# max32657 register map
Vendor: Maxim-Integrated; Series: ARMCM33; File version: 1.1
CPU: CM4 r2p1, little endian, MPU, FPU, 3 interrupt priority bits
Registers are 32-bit, read-write, reset 0x0 unless marked. A register's access mark holds for its fields unless they carry their own. Offsets are from the block's base; [hi:lo] are bit positions; {n}, {i} and the like mark numbered series.

## MCR — Misc Control.
Base 0x50006C00
0x04 RST wo — Reset Register.
  [0] BOOST — Reset BOOST Controller. Write 1 to reset; self-clearing. Register has no read path.
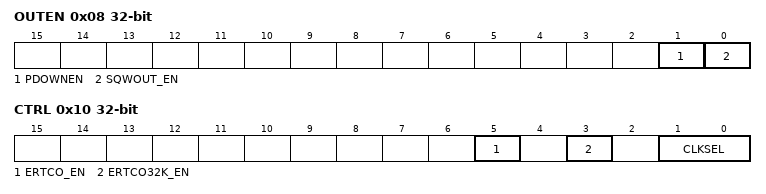
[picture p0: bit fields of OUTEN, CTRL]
0x08 OUTEN — Output Enable Register.
  [1] PDOWNEN — Power Down Enable (vestigial, not connected to functional logic).
  [0] SQWOUT_EN — Square Wave Output Enable.
0x10 CTRL — Control Register
  [5] ERTCO_EN — Enable the ERTCO.
  [3] ERTCO32K_EN — Enable the 32KHz ERTCO.
  [1:0] CLKSEL — Clock Select for the RTC, System, WUT, and Timer.
    0=ERTCO (ERTCO as clock source.); 1=INRO_DIV4 (INRO as clock source.); 2=RTC_IN (P0.12 CLK_EXT (undivided) as 32kHz clock source.)
0x30 BYPASS0 — This register is used by firmware to bypass chain of trust on a Warm Boot.
0x34 BYPASS1 — This register is used by firmware as a secondary bypass word for chain of trust on a Warm Boot.
0x40 DATA0 — Battery Back Data0 Register. Retains value in all modes.
0x44 DATA1 — Battery Back Data1 Register. Retains value in all modes.

## PWRSEQ — Power Sequencer / Low Power Control Register.
Base 0x50006800
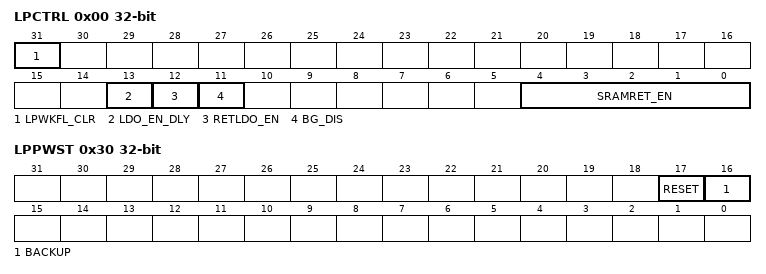
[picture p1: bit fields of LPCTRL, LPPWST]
0x00 LPCTRL — Low Power Control Register.
  [31] LPWKFL_CLR wo write-1-clears — LP wakeup flag register clear. Write 1 to clear all wakeup flags in LPWKFL0.
  [13] LDO_EN_DLY — Core LDO Enable Delay.
    0=dis (Disable.); 1=en (Enable delay LDO power up to smooth LDO voltage drop.)
  [12] RETLDO_EN — Retention LDO Enable.
    0=dis (Disable.); 1=en (Enable.)
  [11] BG_DIS — Bandgap OFF. This controls the System Bandgap in DeepSleep mode.
    0=on (Bandgap is always ON.); 1=off (Bandgap is OFF in DeepSleep mode (default).)
  [4:0] SRAMRET_EN — System RAM retention in BACKUP mode. These bits select which SRAM blocks are retained in BACKUP mode.
0x04 LPWKFL0 — Low Power I/O Wakeup Status Register 0. This register indicates the low power wakeup status for GPIO0.
  [13:0] PINS write-1-clears — Wakeup Flags for GPIO0 pins [13:0]. Each bit corresponds to one GPIO0 pin. Write 1 to clear.
0x08 LPWKEN0 — Low Power I/O Wakeup Enable Register 0. This register enables low power wakeup functionality for GPIO0.
  [13:0] PINS — Enable wakeup for GPIO0 pins [13:0]. Each bit allows wakeup from the corresponding GPIO0 pin on a low-to-high or high-to-low transition when PM.GPIOWKEN is set. Wakeup status is indicated in LPWKFL0.
0x30 LPPWST — Low Power Peripheral Wakeup Status Register.
  [17] RESET write-1-clears — Reset Detected Wakeup Flag. Write 1 to clear.
  [16] BACKUP write-1-clears — BACKUP Wakeful Flag. Write 1 to clear.
0x48 GP0 — General Purpose Register 0
0x4C GP1 — General Purpose Register 1

## MPC — Memory Protection Controller.
Base 0x50091000
Same registers: MPC1 0x50092000, MPC2 0x50093000, MPC3 0x50094000, MPC4 0x50095000, MPC5 0x50096000
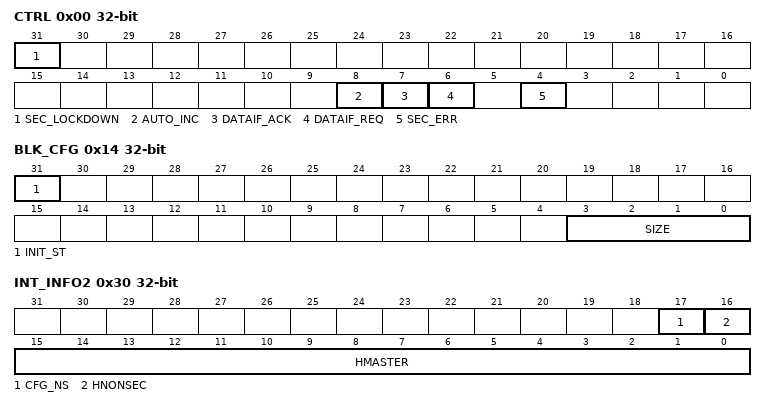
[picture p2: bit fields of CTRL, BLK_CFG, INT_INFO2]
0x00 CTRL — Control Register.
  [31] SEC_LOCKDOWN — Security Lockdown.
  [8] AUTO_INC — Auto-increment.
  [7] DATAIF_ACK — Data interface gating acknowledged.
  [6] DATAIF_REQ — Data interface gating request.
  [4] SEC_ERR — Security Error Response COnfiguration.
0x10 BLK_MAX ro — Maximum value of block-based index register.
  [31:0] VAL
0x14 BLK_CFG ro — Block Control Register.
  [31] INIT_ST — Initialization in progress.
  [3:0] SIZE — Block Size.
0x18 BLK_IDX — Block Index Register.
  [31:0] IDX — Index value for accessing block-based lookup table.
0x1C BLK_LUT — Block-based gating Look Up Table Register.
  [31:0] ACCESS — Each bit indicates one block, based on the index pointed by the BLKIDX register.
0x20 INT_STAT ro — Interrupt Flag Register.
  [0] MPC_IRQ — MPC IRQ triggered.
0x24 INT_CLEAR wo — Interrupt Clear Register.
  [0] MPC_IRQ — MPC IRQ Clear.
0x28 INT_EN — Interrupt Enable Register.
  [0] MPC_IRQ — MPC IRQ Enable.
0x2C INT_INFO1 ro — Interrupt Info 1 Register.
  [31:0] HADDR — AHB bus signals: Address bus.
0x30 INT_INFO2 ro — Interrupt Info 2 Register.
  [17] CFG_NS — Security state.
  [16] HNONSEC — AHB bus signals: Indicates the current transfer is either a Non-Secure or Secure transfer.
  [15:0] HMASTER — AHB bus signals: Master Select.
0x34 INT_SET wo — Interrupt Set Debug Register.
  [0] MPC_IRQ — MPC IRQ Set.
{0xFC0+4i} PIDR{i} ro (i=4..6) — Peripheral ID {i} Register.
0xFDC PIDR7 ro — Peripheral ID 6 Register.
{0xFE0+4i} PIDR{i} ro (i=0..3) — Peripheral ID {i} Register.
{0xFF0+4i} CIDR{i} ro (i=0..3) — Component ID register.
